# MM32F103xx register map
File version: 1.3
Registers are 32-bit, read-write, reset 0x0 unless marked. A register's access mark holds for its fields unless they carry their own. Offsets are from the block's base; [hi:lo] are bit positions.

## RTC — Real time clock
Base 0x40002800
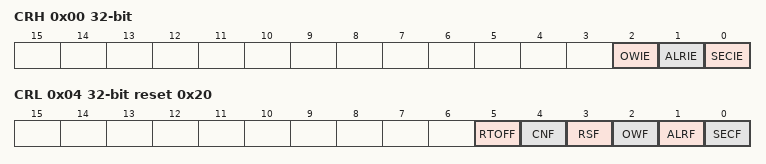
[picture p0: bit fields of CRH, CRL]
0x00 CRH
  [2] OWIE — Overflow interrupt enable
  [1] ALRIE — Alarm interrupt enable
  [0] SECIE — Second interrupt enable
0x04 CRL reset 0x20
  [5] RTOFF — RTC operation OFF
  [4] CNF — Configuration flag
  [3] RSF — Registers synchronized flag
  [2] OWF — Overflow flag
  [1] ALRF — Alarm flag
  [0] SECF — Second flag
0x08 PRLH wo
  [3:0] RTC_PRLH — RTC prescaler reload value high
0x0C PRLL wo
  [15:0] RTC_PRLL — RTC prescaler reload value low
0x10 DIVH ro
  [3:0] RTC_DIVH — RTC clock divider high
0x14 DIVL ro
  [15:0] RTC_DIVL — RTC clock divider low
0x18 CNTH
  [15:0] RTC_CNTH — RTC counter high
0x1C CNTL
  [15:0] RTC_CNTL — RTC counter low
0x20 ALRH wo reset 0xFFFF
  [15:0] RTC_ALRH — RTC alarm high
0x24 ALRL wo reset 0xFFFF
  [15:0] RTC_ALRL — RTC alarm low

## SPI1 — Serial peripheral interface
Base 0x40013000
Same registers: SPI2 0x40003800
0x00 TXREG
  [31:0] TXREG — Transmit data register
0x04 RXREG ro
  [31:0] RXREG — Receive data register
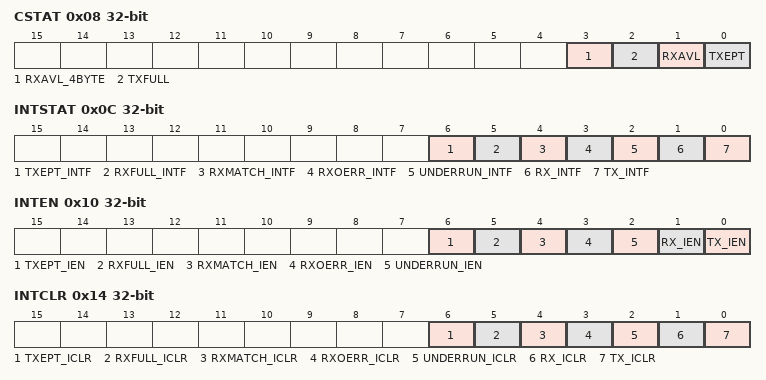
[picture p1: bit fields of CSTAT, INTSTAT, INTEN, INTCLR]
0x08 CSTAT ro
  [3] RXAVL_4BYTE — Receive available 4 byte data message
  [2] TXFULL — Transmitter FIFO full status bit
  [1] RXAVL — Receive available byte data message
  [0] TXEPT — Transmitter empty bit
0x0C INTSTAT
  [6] TXEPT_INTF — Transmitter empty interrupt flag bit
  [5] RXFULL_INTF — RX FIFO full interrupt flag bit
  [4] RXMATCH_INTF — "Receive data match the RXDNR number
  [3] RXOERR_INTF — Receive overrun error interrupt flag bit
  [2] UNDERRUN_INTF — SPI underrun interrupt flag bit
  [1] RX_INTF — Receive data available interrupt flag bit
  [0] TX_INTF — Transmit FIFO avialable interrupt flag bit
0x10 INTEN
  [6] TXEPT_IEN — Transmit empty interrupt enable bit
  [5] RXFULL_IEN — Receive FIFO full interrupt enable bit
  [4] RXMATCH_IEN — Receive data complete interrupt enable bit
  [3] RXOERR_IEN — Overrun error interrupt enable bit
  [2] UNDERRUN_IEN — Transmitter underrun interrupt enable bit(SPI slave mode only)
  [1] RX_IEN — Receive FIFO interrupt enable bit
  [0] TX_IEN — Transmit FIFO empty interrupt enable bit
0x14 INTCLR
  [6] TXEPT_ICLR — Transmitter empty interrupt clear bit
  [5] RXFULL_ICLR — Receiver buffer full interrupt clear bit
  [4] RXMATCH_ICLR — Receive completed interrupt clear bit
  [3] RXOERR_ICLR — Overrun error interrupt clear bit
  [2] UNDERRUN_ICLR — Transmitter underrun interrupt clear bit(SPI slave mode only)
  [1] RX_ICLR — Receive interrupt clear bit
  [0] TX_ICLR — Transmitter FIFO empty interrupt clear bit
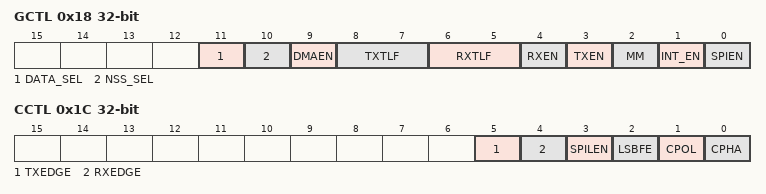
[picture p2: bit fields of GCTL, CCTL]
0x18 GCTL
  [11] DATA_SEL — Valid byte or double-word data select signal
  [10] NSS_SEL — NSS select signal that from software and hardware
  [9] DMAEN — DMA access mode enable
  [8:7] TXTLF — TX FIFO trigger level bit
  [6:5] RXTLF — RX FIFO trigger level bit
  [4] RXEN — Receive enable bit
  [3] TXEN — Transmit enable bit
  [2] MM — Master mode bit
  [1] INT_EN — SPI interrupt enable bit
  [0] SPIEN — SPI select bit
0x1C CCTL
  [5] TXEDGE — Transmit data edge select
  [4] RXEDGE — Receive data edge select
  [3] SPILEN — SPI character length bit
  [2] LSBFE — LSI first enable bit
  [1] CPOL — Clock polarity select bit
  [0] CPHA — Clock phase select bit
0x20 SPBRG
  [31:0] SPBRG — SPI baud rate control register for baud rate
0x24 RXDNR
  [31:0] RXDNR — The register is used to hold a count of to be received bytes in next receive process
0x28 SCSR
  [7:0] CSN — Chip select output signal in Master mode

## UART1 — Universal asynchronous receiver transmitter
Base 0x40013800
Same registers: UART2 0x40004400, UART3 0x40004800
0x00 TDR
  [7:0] TXREG — Transmit data register
0x04 RDR ro
  [7:0] RXREG — Receive data register
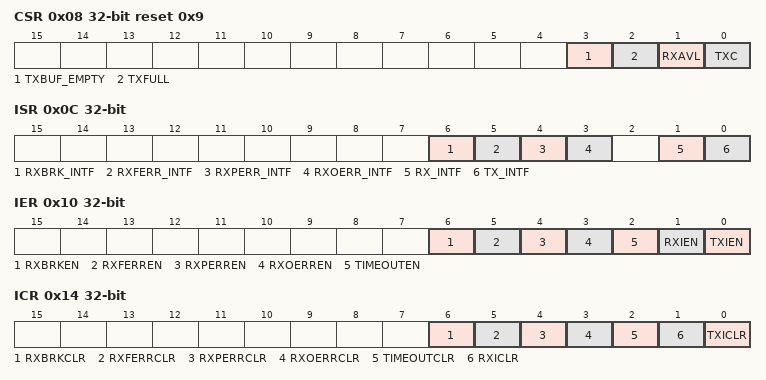
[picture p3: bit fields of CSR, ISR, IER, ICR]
0x08 CSR ro reset 0x9
  [3] TXBUF_EMPTY — Transmit buffer enpty flag bit
  [2] TXFULL — Transmit buffer full flag bit
  [1] RXAVL — Receive valid data flag bit
  [0] TXC — Transmit complete flag bit
0x0C ISR ro
  [6] RXBRK_INTF — Receive frame break interrupt flag bit
  [5] RXFERR_INTF — Frame error interrupt flag bit
  [4] RXPERR_INTF — Parity error interrupt flag bit
  [3] RXOERR_INTF — Receive overflow error interrupt flag bit
  [1] RX_INTF — Receive valid data interrupt flag bit
  [0] TX_INTF — Transmit buffer enpty interrupt flag bit
0x10 IER
  [6] RXBRKEN — Receive frame break interrupt enable bit
  [5] RXFERREN — Frame error interrupt enable bit
  [4] RXPERREN — Parity error interrupt enable bit
  [3] RXOERREN — Receive overflow error interrupt enable bit
  [2] TIMEOUTEN — Receive timeout interrupt enable bit
  [1] RXIEN — Receive buffer interrupt enable bit
  [0] TXIEN — Transmit buffer enpty interrupt enable bit
0x14 ICR wo
  [6] RXBRKCLR — Receive frame break interrupt clear bit
  [5] RXFERRCLR — Frame error interrupt clear bit
  [4] RXPERRCLR — Parity error interrupt clear bit
  [3] RXOERRCLR — Receive overflow error interrupt clear bit
  [2] TIMEOUTCLR — Receive timeout interrupt clear bit
  [1] RXICLR — Receive interrupt clear bit
  [0] TXICLR — Transmit buffer empty interrupt clear bit
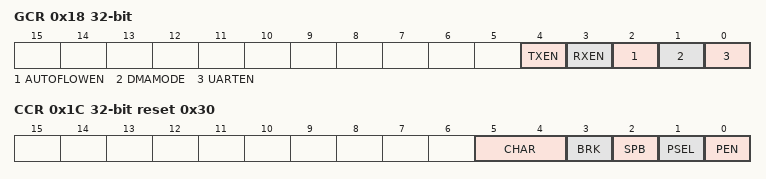
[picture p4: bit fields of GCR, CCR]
0x18 GCR
  [4] TXEN — Enable transmit
  [3] RXEN — Enable receive
  [2] AUTOFLOWEN — Automatic flow control enable bit
  [1] DMAMODE — DMA mode selection bit
  [0] UARTEN — UART mode selection bit
0x1C CCR reset 0x30
  [5:4] CHAR — UART width bit
  [3] BRK — UART transmit frame break
  [2] SPB — Stop bit selection
  [1] PSEL — Parity selection bit
  [0] PEN — Parity enable bit
0x20 BRR reset 0x1
  [15:0] SPBRG — UART baud rate control register
